VERSION ""

NS_ :

BS_:

BU_: VCU FIA_MLS
VAL_TABLE_ BAccident 1 "Accident detected and recorded" 0 "No accident detected" ;
VAL_TABLE_ NHighPowerScenario 5 "6 + 2 min" 4 "5 + 3 min" 3 "4 + 4 min" 2 "3 + 5 min" 1 "2 + 6 min" ;
VAL_TABLE_ RCS_Flag 17 "DOUBLE YELLOW" 16 "Do not use" 15 "Do not use" 14 "SC - IN" 13 "SC" 12 "Do not use" 11 "FINISH" 10 "SLIPPERY" 9 "FCY" 8 "WHITE" 7 "YELLOW" 6 "Do not use" 5 "BLACK&WHITE" 4 "BLACK" 3 "RED" 2 "BLUE" 1 "GREEN" 0 "No Flag displayed" ;
VAL_TABLE_ NMux165 2 "Current PTT Beep settings" 1 "Current volume config" ;
VAL_TABLE_ NMux164 4 "PTT Default settings" 3 "Audio Default settings" 2 "PTT Custom settings" 1 "Audio Custom settings" ;
VAL_TABLE_ PowerMode 3 "350kW" 2 "300kW" 1 "110kW" ;
VAL_TABLE_ CarManufacturer_FIA 10 "Porsche" 9 "Penske" 8 "Mercedes" 7 "NIO" 6 "Mahindra" 5 "Jaguar" 4 "DS" 3 "Nissan" 2 "BMW" 1 "Audi" 0 "None" ;

BO_ 389 FIA_2_ECU_0x185: 8 FIA_MLS
 SG_ ERaceAvailable_FIA : 7|12@0+ (0.05,0) [0|204.75] "kWh"  VCU

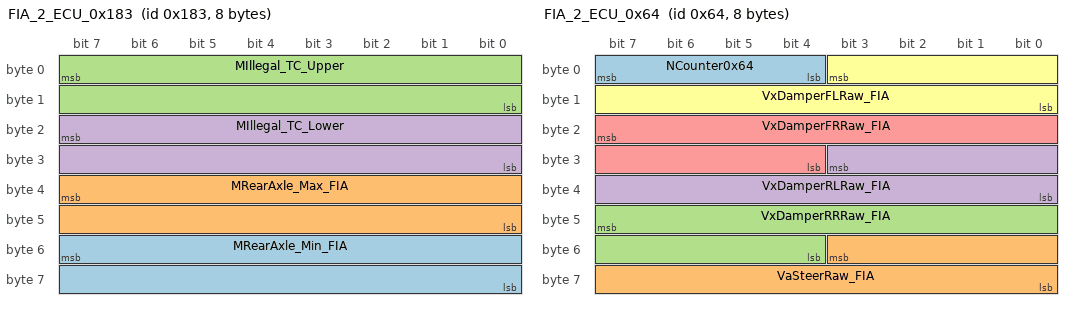
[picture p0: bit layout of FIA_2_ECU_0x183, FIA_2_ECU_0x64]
BO_ 387 FIA_2_ECU_0x183: 8 FIA_MLS
 SG_ MRearAxle_Min_FIA : 55|16@0+ (0.1,-1000) [-1000|5553.5] "Nm"  VCU
 SG_ MRearAxle_Max_FIA : 39|16@0+ (0.1,-1000) [-1000|5553.5] "Nm"  VCU
 SG_ MIllegal_TC_Upper : 7|16@0+ (0.01,0) [0|655.35] "Nm.s"  VCU
 SG_ MIllegal_TC_Lower : 23|16@0+ (0.01,0) [0|655.35] "Nm.s"  VCU

BO_ 1280 ECU_2_FIA_0x500: 3 VCU
 SG_ MotTqCmd : 11|12@0+ (0.5,-1000) [-1000|1000] "Nm"  FIA_MLS
 SG_ vcuPressureTarget : 7|12@0+ (0.05,0) [0|204.75] "bar"  FIA_MLS

BO_ 100 FIA_2_ECU_0x64: 8 FIA_MLS
 SG_ NCounter0x64 : 7|4@0+ (1,0) [0|15] ""  VCU
 SG_ VaSteerRaw_FIA : 51|12@0+ (1.2210012210012,0) [0|4999.99999999991] "mV"  VCU
 SG_ VxDamperRRRaw_FIA : 47|12@0+ (1.2210012210012,0) [0|4999.99999999991] "mV"  VCU
 SG_ VxDamperRLRaw_FIA : 27|12@0+ (1.2210012210012,0) [0|4999.99999999991] "mV"  VCU
 SG_ VxDamperFRRaw_FIA : 23|12@0+ (1.2210012210012,0) [0|4999.99999999991] "mV"  VCU
 SG_ VxDamperFLRaw_FIA : 3|12@0+ (1.2210012210012,0) [0|4999.99999999991] "mV"  VCU

BO_ 106 DRLFromM: 5 FIA_MLS
 SG_ MMDRLMeasured : 20|20@1- (0.015625,0) [-8192|8191.984375] "Nm"  VCU
 SG_ NMDRLFromMMux M : 16|2@1+ (1,0) [0|3] ""  VCU
 SG_ MMDRLMeasuredPeakNeg m2 : 0|16@1- (0.25,0) [-8192|8191.75] "Nm"  VCU
 SG_ MMDRLMeasuredPeakPos m1 : 0|16@1- (0.25,0) [-8192|8191.75] "Nm"  VCU

BO_ 111 DRRFromM: 5 FIA_MLS
 SG_ MMDRRMeasured : 20|20@1- (0.015625,0) [-8192|8191.984375] "Nm"  VCU
 SG_ NMDRRFromMMux M : 16|2@1+ (1,0) [0|3] ""  VCU
 SG_ MMDRRMeasuredPeakNeg m2 : 0|16@1- (0.25,0) [-8192|8191.75] "Nm"  VCU
 SG_ MMDRRMeasuredPeakPos m1 : 0|16@1- (0.25,0) [-8192|8191.75] "Nm"  VCU

BO_ 365 FIA_2_ECU_0x16D: 8 FIA_MLS
 SG_ IVT1_Result_U1_FMGU : 39|32@0- (1,0) [-2147483648|2147483647] "mV"  VCU
 SG_ IVT1_Result_I_FMGU : 7|32@0- (1,0) [-2147483648|2147483647] "mA"  VCU

BO_ 367 FIA_2_ECU_0x16F: 8 FIA_MLS
 SG_ IVT3_Result_I_DCDC : 39|32@0- (1,0) [-2147483648|2147483647] "mA"  VCU
 SG_ IVT2_Result_I_RMGU : 7|32@0- (1,0) [-2147483648|2147483647] "mA"  VCU

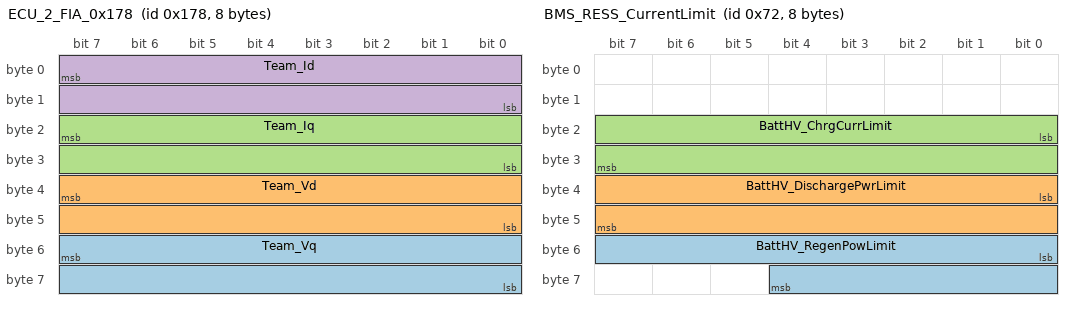
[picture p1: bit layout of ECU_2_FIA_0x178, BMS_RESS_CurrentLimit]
BO_ 376 ECU_2_FIA_0x178: 8 VCU
 SG_ Team_Vq : 55|16@0- (0.1,0) [-3276.8|3276.7] "V"  FIA_MLS
 SG_ Team_Vd : 39|16@0- (0.1,0) [-3276.8|3276.7] "V"  FIA_MLS
 SG_ Team_Iq : 23|16@0- (0.1,0) [-3276.8|3276.7] "A"  FIA_MLS
 SG_ Team_Id : 7|16@0- (0.1,0) [-3276.8|3276.7] "A"  FIA_MLS

BO_ 114 BMS_RESS_CurrentLimit: 8 FIA_MLS
 SG_ BattHV_RegenPowLimit : 48|13@1+ (0.1,0) [0|819.1] "kW"  VCU
 SG_ BattHV_DischargePwrLimit : 32|16@1+ (0.05,-3276.75) [-3276.75|0] "kW"  VCU
 SG_ BattHV_ChrgCurrLimit : 16|16@1+ (0.05,0) [0|3276.75] "A"  VCU

BO_ 112 BMS_RESS_Status: 8 FIA_MLS
 SG_ BMS_FaultActive_FR4 : 47|1@1+ (1,0) [0|1] ""  VCU
 SG_ Batt_SafetyLightStatRedFIA : 46|1@1+ (1,0) [0|1] ""  VCU
 SG_ Batt_SafetyLightStatGreenFIA : 45|1@1+ (1,0) [0|1] ""  VCU
 SG_ BMS_CAL_ID : 24|8@1+ (1,0) [0|255] ""  VCU
 SG_ BMS_SW_ID : 16|8@1+ (1,0) [0|255] ""  VCU
 SG_ Batt_ReadytoTurnOnHV : 15|1@1+ (1,0) [0|1] ""  VCU
 SG_ Batt_ReadyforBoostCharge : 14|1@1+ (1,0) [0|1] ""  VCU
 SG_ Batt_Isolation2Status : 13|1@1+ (1,0) [0|1] ""  VCU
 SG_ Batt_Isolation1Status : 12|1@1+ (1,0) [0|1] ""  VCU
 SG_ BMS_ErrorFR7 : 7|1@1+ (1,0) [0|1] ""  VCU
 SG_ BMS_ErrorFR6 : 6|1@1+ (1,0) [0|1] ""  VCU
 SG_ BattHV_MinSOC : 56|8@1+ (0.5,0) [0|127.5] "%"  VCU
 SG_ BattHV_MaxSOC : 48|8@1+ (0.5,0) [0|127.5] "%"  VCU
 SG_ MainPOS_Contactor_Status : 42|1@1+ (1,0) [0|1] ""  VCU
 SG_ VehicleWorkingMode : 36|4@1+ (1,0) [0|15] ""  VCU
 SG_ InvNEG_Contactor_Status : 41|1@1+ (1,0) [0|1] ""  VCU
 SG_ ChrgPOS_Contactor_Status : 43|1@1+ (1,0) [0|1] ""  VCU
 SG_ ChrgNEG_Contactor_Status : 44|1@1+ (1,0) [0|1] ""  VCU
 SG_ Cell_Under_V_Flag : 10|1@1+ (1,0) [0|1] ""  VCU
 SG_ Cell_Under_T_Flag : 11|1@1+ (1,0) [0|1] ""  VCU
 SG_ Cell_Over_V_Flag : 8|1@1+ (1,0) [0|1] ""  VCU
 SG_ Cell_Over_T_Flag : 9|1@1+ (1,0) [0|1] ""  VCU
 SG_ BMSstatus : 32|4@1+ (1,0) [0|15] ""  VCU
 SG_ BMS_ErrorFR5 : 5|1@1+ (1,0) [0|1] ""  VCU
 SG_ BMS_ErrorFR4 : 4|1@1+ (1,0) [0|1] ""  VCU
 SG_ BMS_ErrorFR3 : 3|1@1+ (1,0) [0|1] ""  VCU
 SG_ BMS_ErrorFR2 : 2|1@1+ (1,0) [0|1] ""  VCU
 SG_ BMS_ErrorFR1 : 1|1@1+ (1,0) [0|1] ""  VCU
 SG_ BMS_ErrorFR0 : 0|1@1+ (1,0) [0|1] ""  VCU
 SG_ AncNEG_Contactor_Status : 40|1@1+ (1,0) [0|1] ""  VCU

BO_ 1055 FIA_Forbidden13: 8 FIA_MLS

BO_ 1054 FIA_Forbidden12: 8 FIA_MLS

BO_ 1053 FIA_Forbidden11: 8 FIA_MLS

BO_ 1052 FIA_Forbidden10: 8 FIA_MLS

BO_ 1039 FIA_Forbidden09: 8 FIA_MLS

BO_ 1038 FIA_Forbidden08: 8 FIA_MLS

BO_ 1037 FIA_Forbidden07: 8 FIA_MLS

BO_ 1036 FIA_Forbidden06: 8 FIA_MLS

BO_ 128 FIA_Forbidden05: 8 FIA_MLS

BO_ 1147 FIA_Forbidden04: 8 FIA_MLS

BO_ 1146 FIA_Forbidden03: 8 FIA_MLS

BO_ 1145 FIA_Forbidden02: 8 FIA_MLS

BO_ 1144 FIA_Forbidden01: 8 FIA_MLS

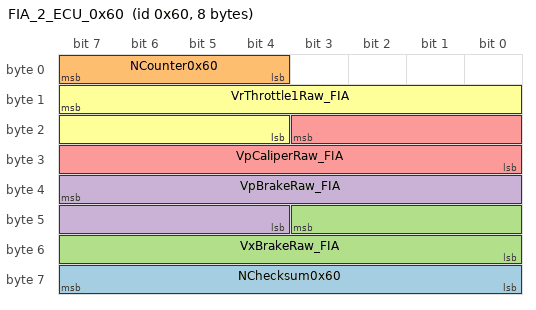
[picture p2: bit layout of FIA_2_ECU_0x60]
BO_ 96 FIA_2_ECU_0x60: 8 FIA_MLS
 SG_ NChecksum0x60 : 63|8@0+ (1,0) [0|255] ""  VCU
 SG_ NCounter0x60 : 7|4@0+ (1,0) [0|15] ""  VCU
 SG_ VxBrakeRaw_FIA : 43|12@0+ (1.2210012210012,0) [0|4999.99999999991] "mV"  VCU
 SG_ VpBrakeRaw_FIA : 39|12@0+ (1.2210012210012,0) [0|4999.99999999991] "mV"  VCU
 SG_ VpCaliperRaw_FIA : 19|12@0+ (1.2210012210012,0) [0|4999.99999999991] "mV"  VCU
 SG_ VrThrottle1Raw_FIA : 15|12@0+ (1.2210012210012,0) [0|4999.99999999991] "mV"  VCU

BO_ 369 FIA_2_ECU_0x171: 8 FIA_MLS
 SG_ IVT4_Result_U1_Charge : 39|32@0- (1,0) [-2147483648|2147483647] "mV"  VCU
 SG_ IVT4_Result_I_Charge : 7|32@0- (1,0) [-2147483648|2147483647] "mA"  VCU

CM_ BO_ 389 "FIA Total race energy available";
CM_ SG_ 389 ERaceAvailable_FIA "Total race energy available - affected by Boost Charge energy addition. Need to make an energy reset to clear the Boost Charge energy addition";
CM_ BO_ 387 "On Throttle - Torque - Delta control";
CM_ SG_ 387 MRearAxle_Min_FIA "FIA on throttle corridor max value";
CM_ SG_ 387 MRearAxle_Max_FIA "FIA on throttle corridor max value";
CM_ SG_ 387 MIllegal_TC_Upper "FIA on throttle control illegal value - based on driveshaft torquemeters - Upper band";
CM_ SG_ 387 MIllegal_TC_Lower "FIA on throttle control illegal value - based on driveshaft torquemeters - Lower band";
CM_ BO_ 1280 "Copy of OEM VCU requests to CAN BBW-Main and CAN FPK-Main (only for pressure and torque targets)";
CM_ SG_ 1280 MotTqCmd "Exact copy of FPK Motor Torque Command sent on CAN FPK-Main";
CM_ SG_ 1280 vcuPressureTarget "Exact copy of BBW Pressure Target sent on CAN BBW-Main";
CM_ BO_ 100 "Damper / Steer";
CM_ SG_ 100 NCounter0x64 "Rolling counter - incremented each time a message is sent";
CM_ SG_ 100 VaSteerRaw_FIA "MLS Ana04";
CM_ SG_ 100 VxDamperRRRaw_FIA "MLS Ana16";
CM_ SG_ 100 VxDamperRLRaw_FIA "MLS Ana17";
CM_ SG_ 100 VxDamperFRRaw_FIA "MLS Ana10";
CM_ SG_ 100 VxDamperFLRaw_FIA "MLS Ana09";
CM_ BO_ 106 "Left Driveshaft torquemeter from CAN FIA";
CM_ BO_ 111 "Right Driveshaft torquemeter from CAN FIA";
CM_ BO_ 365 "IVTS 1 Front MGU Voltage / Current";
CM_ SG_ 365 IVT1_Result_U1_FMGU "IVTS1 Front MGU Voltage measurement. Due to sensor installation the measured Voltage is negative";
CM_ SG_ 365 IVT1_Result_I_FMGU "IVTS1 Front MGU Current measurement. + Regen / - Release";
CM_ BO_ 367 "IVTS 2 Rear MGU Current / IVTS 3 DCDC Current";
CM_ SG_ 367 IVT3_Result_I_DCDC "IVTS3 DCDC Current measurement. + for current consummed from the RESS";
CM_ SG_ 367 IVT2_Result_I_RMGU "IVTS2 Rear MGU Current measurement. - Regen / + Release";
CM_ BO_ 376 "Rear inverter model field-oriented control Id, Iq, Vd, Vq";
CM_ SG_ 376 Team_Vq "Rear inverter";
CM_ SG_ 376 Team_Vd "Rear inverter";
CM_ SG_ 376 Team_Iq "Rear inverter";
CM_ SG_ 376 Team_Id "Rear inverter";
CM_ BO_ 114 "Redundancy message from CAN FIA - BMS. FIA logger act as a CAN bridge, if BMS stop sending this message on CAN FIA the FIA logger will stop sending it back on CAN TPMS.";
CM_ SG_ 114 BattHV_RegenPowLimit "Regen Power Limit kW";
CM_ SG_ 114 BattHV_DischargePwrLimit "Discharge Power Limit kW";
CM_ BO_ 112 "Redundancy message from CAN FIA - BMS. FIA logger act as a CAN bridge, if BMS stop sending this message on CAN FIA the FIA logger will stop sending it back on CAN TPMS.";
CM_ SG_ 112 BMS_FaultActive_FR4 "FR4 Fault Live Status Signal";
CM_ SG_ 112 Batt_SafetyLightStatRedFIA "Safety light status Red";
CM_ SG_ 112 Batt_SafetyLightStatGreenFIA "Safety Light Status Green";
CM_ SG_ 112 BMS_CAL_ID "Bettery Cal ID";
CM_ SG_ 112 BMS_SW_ID "SW Release number";
CM_ BO_ 1055 "Reserved IDs for Marelli system - DO NOT USE";
CM_ BO_ 1054 "Reserved IDs for Marelli system - DO NOT USE";
CM_ BO_ 1053 "Reserved IDs for Marelli system - DO NOT USE";
CM_ BO_ 1052 "Reserved IDs for Marelli system - DO NOT USE";
CM_ BO_ 1039 "Reserved IDs for Marelli system - DO NOT USE";
CM_ BO_ 1038 "Reserved IDs for Marelli system - DO NOT USE";
CM_ BO_ 1037 "Reserved IDs for Marelli system - DO NOT USE";
CM_ BO_ 1036 "Reserved IDs for Marelli system - DO NOT USE";
CM_ BO_ 128 "Reserved IDs for Marelli system - DO NOT USE";
CM_ BO_ 1147 "Reserved IDs for Marelli system - DO NOT USE";
CM_ BO_ 1146 "Reserved IDs for Marelli system - DO NOT USE";
CM_ BO_ 1145 "Reserved IDs for Marelli system - DO NOT USE";
CM_ BO_ 1144 "Reserved IDs for Marelli system - DO NOT USE";
CM_ BO_ 96 "Throttle / Brake";
CM_ SG_ 96 NChecksum0x60 "Sum of the 7 first bytes";
CM_ SG_ 96 NCounter0x60 "Rolling counter - incremented each time a message is sent";
CM_ SG_ 96 VxBrakeRaw_FIA "MLS Ana08";
CM_ SG_ 96 VpBrakeRaw_FIA "MLS Ana06";
CM_ SG_ 96 VpCaliperRaw_FIA "MLS Ana03";
CM_ SG_ 96 VrThrottle1Raw_FIA "MLS Ana01";
CM_ BO_ 369 "IVTS 4 Charger input Voltage / Current";
CM_ SG_ 369 IVT4_Result_U1_Charge "IVTS4 Charger Voltage measurement. Due to sensor installation the measured Voltage is negative";
CM_ SG_ 369 IVT4_Result_I_Charge "IVTS4 Charger Current measurement. + when charging the RESS";
BA_DEF_ SG_  "GenSigEnvVarType" ENUM  "int","float","undef";
BA_DEF_ SG_  "GenSigSendType" ENUM  "Cyclic","OnWrite","OnWriteWithRepetition","OnChange","OnChangeWithRepetition","IfActive","IfActiveWithRepetition","NoSigSendType","NotUsed","NotUsed","NotUsed","NotUsed","NotUsed";
BA_DEF_ SG_  "GenSigStartValue" INT 0 0;
BA_DEF_ BO_  "GenMsgILSupport" ENUM  "No","Yes";
BA_DEF_ BO_  "GenMsgMinAcceptLength" INT 0 0;
BA_DEF_ BO_  "GenMsgSendType" ENUM  "Cyclic","NotUsed","NotUsed","NotUsed","NotUsed","NotUsed","NotUsed","IfActive","NoMsgSendType","NotUsed";
BA_DEF_ BO_  "GenMsgCycleTime" INT 0 0;
BA_DEF_ BU_  "ILUsed" ENUM  "No","Yes";
BA_DEF_ BU_  "NmNode" ENUM  "No","Yes";
BA_DEF_  "DBName" STRING ;
BA_DEF_  "GenNWMSleepTime" INT 0 10000000;
BA_DEF_  "ILTxTimeout" INT 0 10000;
BA_DEF_  "NBTMax" INT 0 255;
BA_DEF_  "NBTMin" INT 0 255;
BA_DEF_  "NmBaseAddress" INT 0 0;
BA_DEF_  "NmMessageCount" INT 0 64;
BA_DEF_  "SamplePointMax" FLOAT 0 100;
BA_DEF_  "SamplePointMin" FLOAT 0 100;
BA_DEF_  "Version" HEX 0 255;
BA_DEF_  "VersionWeek" INT 0 53;
BA_DEF_  "VersionYear" INT 0 99;
BA_DEF_  "Manufacturer" STRING ;
BA_DEF_  "Baudrate" INT 0 1000000;
BA_DEF_  "BusType" STRING ;
BA_DEF_ BU_  "ECU" STRING ;
BA_DEF_DEF_  "GenSigEnvVarType" "undef";
BA_DEF_DEF_  "GenSigSendType" "Cyclic";
BA_DEF_DEF_  "GenSigStartValue" 0;
BA_DEF_DEF_  "GenMsgILSupport" "Yes";
BA_DEF_DEF_  "GenMsgMinAcceptLength" 8;
BA_DEF_DEF_  "GenMsgSendType" "Cyclic";
BA_DEF_DEF_  "GenMsgCycleTime" 0;
BA_DEF_DEF_  "ILUsed" "Yes";
BA_DEF_DEF_  "NmNode" "Yes";
BA_DEF_DEF_  "DBName" "";
BA_DEF_DEF_  "GenNWMSleepTime" 10000000;
BA_DEF_DEF_  "ILTxTimeout" 30;
BA_DEF_DEF_  "NBTMax" 21;
BA_DEF_DEF_  "NBTMin" 9;
BA_DEF_DEF_  "NmBaseAddress" 1024;
BA_DEF_DEF_  "NmMessageCount" 64;
BA_DEF_DEF_  "SamplePointMax" 81.25;
BA_DEF_DEF_  "SamplePointMin" 75;
BA_DEF_DEF_  "Version" 160;
BA_DEF_DEF_  "VersionWeek" 6;
BA_DEF_DEF_  "VersionYear" 7;
BA_DEF_DEF_  "Manufacturer" "FIA";
BA_DEF_DEF_  "Baudrate" 125000;
BA_DEF_DEF_  "BusType" "";
BA_DEF_DEF_  "ECU" "";
BA_ "NmMessageCount" 0;
BA_ "NmBaseAddress" 0;
BA_ "BusType" "CAN";
BA_ "DBName" "FIALogger_FEGen3_CAN1_V12";
BA_ "ECU" BU_ VCU "TEAM_ECU";
BA_ "ECU" BU_ FIA_MLS "FIA_MLS";
BA_ "GenMsgCycleTime" BO_ 389 1000;
BA_ "GenMsgCycleTime" BO_ 387 10;
BA_ "GenMsgCycleTime" BO_ 1280 2;
BA_ "GenMsgCycleTime" BO_ 100 2;
BA_ "GenMsgCycleTime" BO_ 106 1;
BA_ "GenMsgCycleTime" BO_ 111 1;
BA_ "GenMsgCycleTime" BO_ 365 2;
BA_ "GenMsgCycleTime" BO_ 367 2;
BA_ "GenMsgCycleTime" BO_ 376 5;
BA_ "GenMsgCycleTime" BO_ 114 20;
BA_ "GenMsgCycleTime" BO_ 112 50;
BA_ "GenMsgCycleTime" BO_ 96 1;
BA_ "GenMsgCycleTime" BO_ 369 2;
BA_ "GenSigStartValue" SG_ 387 MRearAxle_Min_FIA 10000;
BA_ "GenSigStartValue" SG_ 387 MRearAxle_Max_FIA 10000;
BA_ "GenSigStartValue" SG_ 1280 MotTqCmd 2000;
VAL_ 112 BMS_FaultActive_FR4 1 "Fault" 0 "No Fault" ;
VAL_ 112 Batt_SafetyLightStatRedFIA 1 "On" 0 "Off" ;
VAL_ 112 Batt_SafetyLightStatGreenFIA 1 "On" 0 "Off" ;
VAL_ 112 MainPOS_Contactor_Status 1 "Close" 0 "Open" ;
VAL_ 112 VehicleWorkingMode 9 "RaceCharge" 8 "DischargeForTransport" 7 "ReadyToDrive" 6 "HVOn" 5 "N/A" 4 "HVCharge" 3 "HVChargePrep" 2 "N/A" 1 "LVOn" 0 "OFF" ;
VAL_ 112 InvNEG_Contactor_Status 1 "Close" 0 "Open" ;
VAL_ 112 ChrgPOS_Contactor_Status 1 "Close" 0 "Open" ;
VAL_ 112 ChrgNEG_Contactor_Status 1 "Close" 0 "Open" ;
VAL_ 112 Cell_Under_V_Flag 1 "Fault" 0 "No Fault" ;
VAL_ 112 Cell_Under_T_Flag 1 "Fault" 0 "No Fault" ;
VAL_ 112 Cell_Over_V_Flag 1 "Fault" 0 "No Fault" ;
VAL_ 112 Cell_Over_T_Flag 1 "Fault" 0 "No Fault" ;
VAL_ 112 BMSstatus 14 "Discharge Transport" 13 "Inverters Powered" 12 "Inverters Precharge" 11 "Bus Discharging" 10 "Self Wake" 9 "Fault Mode" 8 "Shutting Down" 7 "CCS2 Charge" 6 "Race Charge" 5 "Charge Prep" 4 "Ancillaries Powered" 3 "Ancillaries Precharge" 2 "Standby" 1 "Initialising" 0 "Off" ;
VAL_ 112 BMS_ErrorFR5 1 "Fault" 0 "No Fault" ;
VAL_ 112 BMS_ErrorFR4 1 "Fault" 0 "No Fault" ;
VAL_ 112 BMS_ErrorFR3 1 "Fault" 0 "No Fault" ;
VAL_ 112 BMS_ErrorFR2 1 "Fault" 0 "No Fault" ;
VAL_ 112 BMS_ErrorFR1 1 "Fault" 0 "No Fault" ;
VAL_ 112 BMS_ErrorFR0 1 "Fault" 0 "No Fault" ;
VAL_ 112 AncNEG_Contactor_Status 1 "Close" 0 "Open" ;
